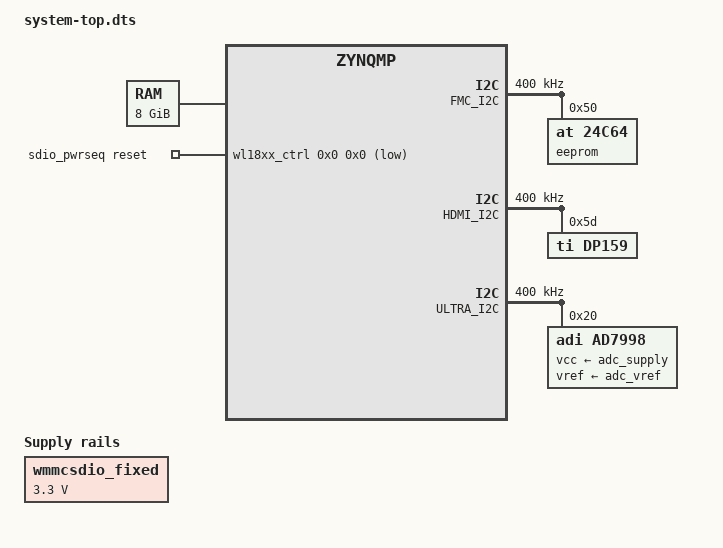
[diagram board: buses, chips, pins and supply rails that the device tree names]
/*
 * CAUTION: This file is automatically generated by Xilinx.
 * Version:  
 * Today is: Thu Oct 25 11:07:18 2018
 */


/dts-v1/;
/include/ "zynqmp.dtsi"
/include/ "zynqmp-clk-ccf.dtsi"
/include/ "pl.dtsi"
/include/ "pcw.dtsi"
/ {
	chosen {
		bootargs = "earlycon clk_ignore_unused";
		stdout-path = "serial0:115200n8";
	};
	aliases {
		ethernet0 = &gem1;
		ethernet1 = &gem2;
		i2c0 = &i2c0;
		serial0 = &uart1;
		serial1 = &uart0;
		spi0 = &qspi;
	};
	memory {
		device_type = "memory";
		reg = <0x0 0x0 0x0 0x7ff00000>, <0x00000008 0x00000000 0x00000001 0x80000000>;
	};
	wmmcsdio_fixed: fixedregulator {
		compatible = "regulator-fixed";
		regulator-name = "wmmcsdio_fixed";
		regulator-min-microvolt = <3300000>;
		regulator-max-microvolt = <3300000>;
		//gpio = <&wl18xx_ctrl 0x0 0x0 0x0>;
		regulator-always-on;
		startup-delay-us = <70000>;
		enable-active-high;
	};
	sdio_pwrseq: sdio_pwrseq {
		compatible = "mmc-pwrseq-simple";
		reset-gpios = <&wl18xx_ctrl 0x0 0x0 0x1>;
		post-power-on-delay-ms = <1000>;
	};
	xlnx {
		compatible = "xlnx,xlnk-1.0";
	};
};
&FMC_I2C {
	status = "okay";
	clock-frequency = <400000>;
	
	eeprom@50 {
		compatible = "at,24c64";
		reg = <0x50>;
	};
};
&HDMI_I2C {
	status = "okay";
	clock-frequency = <400000>;

	dp159: hdmi-retimer@5d {
		status = "okay";
		compatible = "ti,dp159";
		reg = <0x5d>;
		#address-cells = <1>;
		#size-cells = <0>;
		#clock-cells = <0>;
	};
};
&ULTRA_I2C {
	clock-frequency = <400000>;
	status = "okay";
	
	ad7998@20 {
		compatible = "adi,ad7998";
		reg = <0x20>;
		vcc-supply = <&adc_supply>;
		vref-supply = <&adc_vref>;
	};
};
